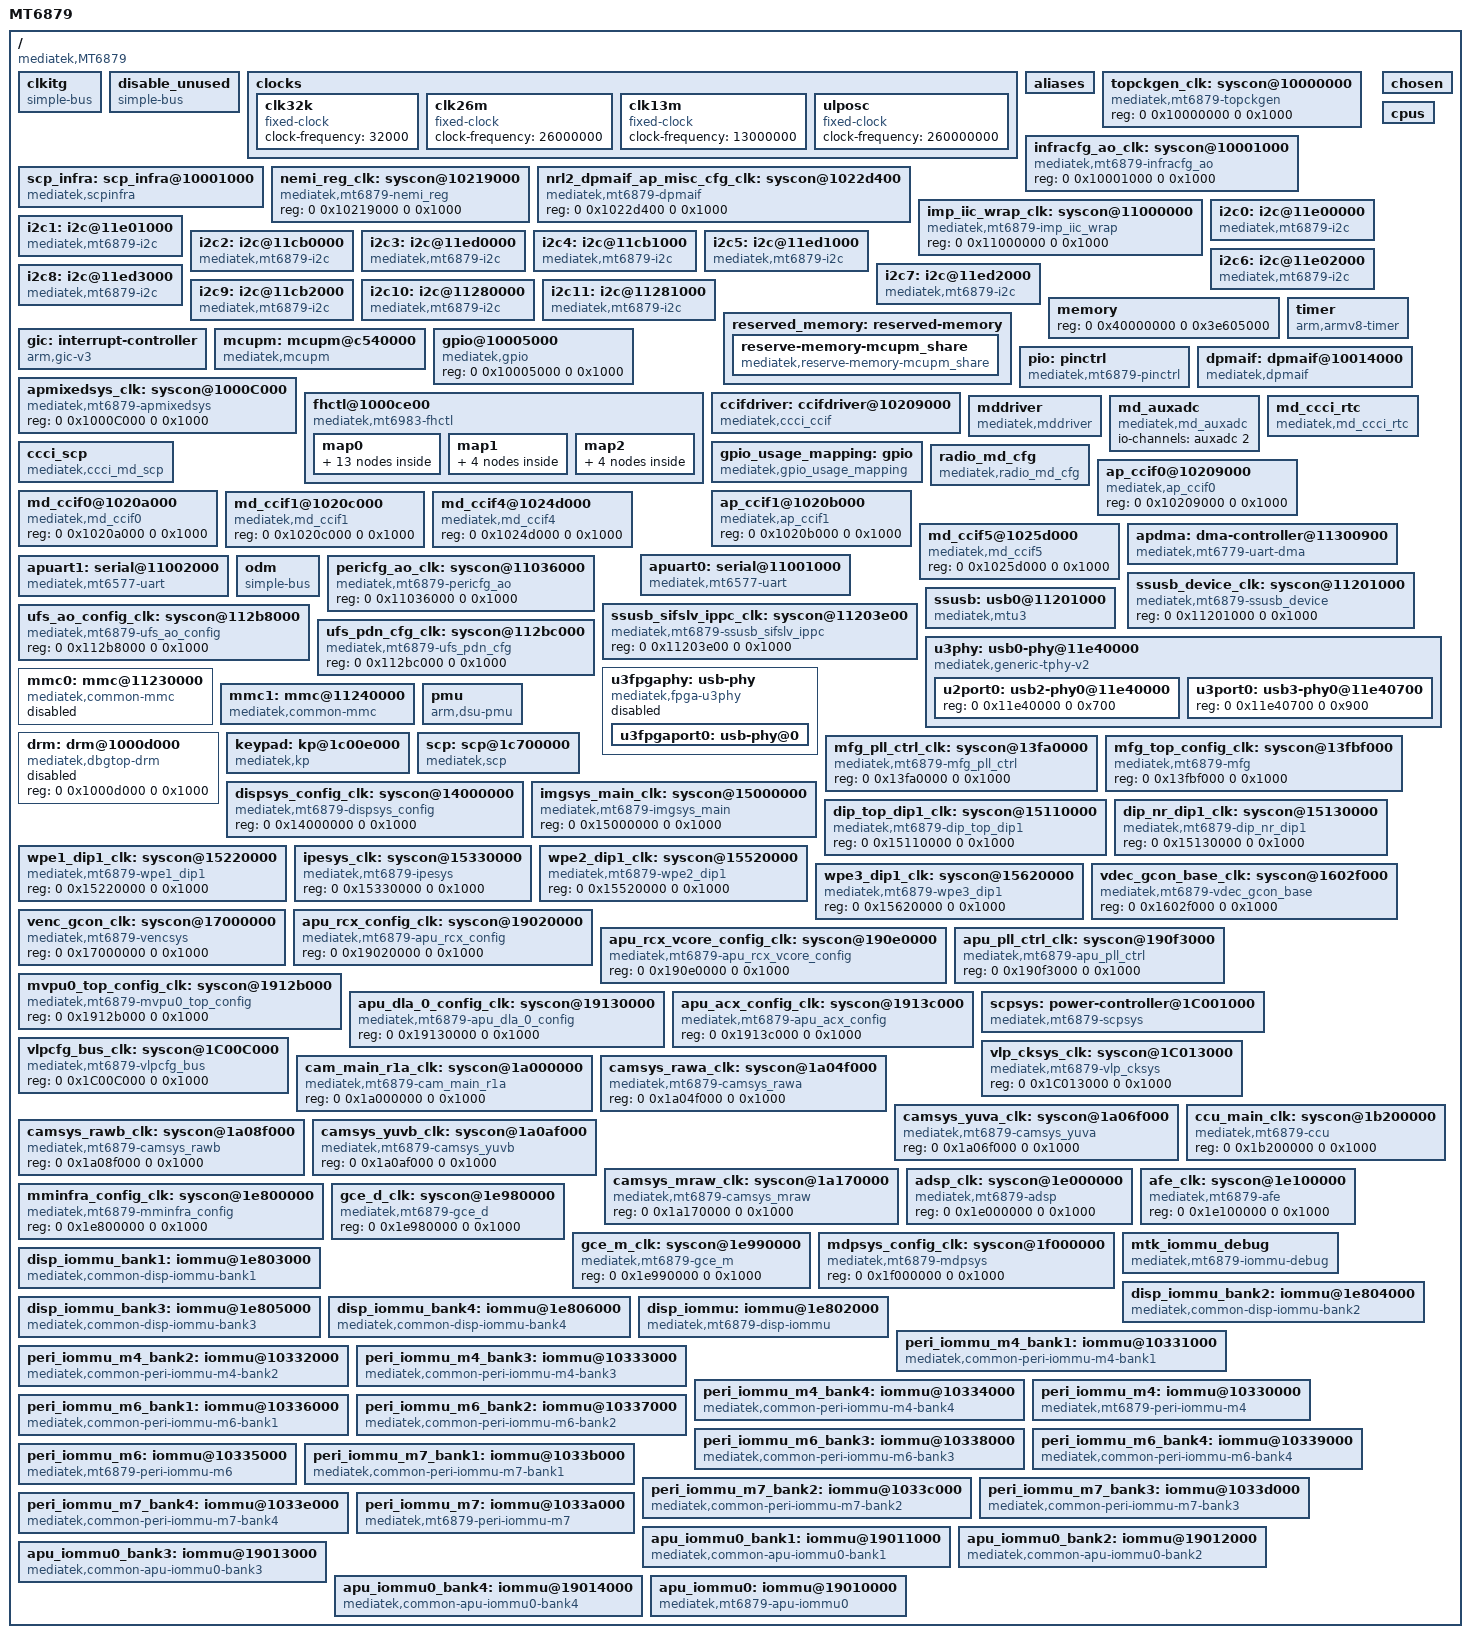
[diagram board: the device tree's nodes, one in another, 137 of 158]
// SPDX-License-Identifier: (GPL-2.0 OR MIT)
/*
 * Copyright (C) 2021 MediaTek Inc.
 */

/dts-v1/;
#include <dt-bindings/clock/mt6879-clk.h>
#include <dt-bindings/interrupt-controller/arm-gic.h>
#include <dt-bindings/interrupt-controller/irq.h>
#include <dt-bindings/phy/phy.h>
#include <dt-bindings/power/mt6879-power.h>
#include <dt-bindings/memory/mt6879-larb-port.h>

/ {
	model = "MT6879";
	compatible = "mediatek,MT6879";
	interrupt-parent = <&gic>;
	#address-cells = <2>;
	#size-cells = <2>;

	clkitg: clkitg {
		compatible = "simple-bus";
	};

	disable_unused: disable_unused {
		compatible = "simple-bus";
	};

	clocks {
		clk32k: clk32k {
			compatible = "fixed-clock";
			#clock-cells = <0>;
			clock-frequency = <32000>;
		};

		clk26m: clk26m {
			compatible = "fixed-clock";
			#clock-cells = <0>;
			clock-frequency = <26000000>;
		};

		clk13m: clk13m {
			compatible = "fixed-clock";
			#clock-cells = <0>;
			clock-frequency = <13000000>;
		};

		ulposc: ulposc {
			compatible = "fixed-clock";
			#clock-cells = <0>;
			clock-frequency = <260000000>;
		};
	};

	aliases {
		i2c0 = &i2c0;
		i2c1 = &i2c1;
		i2c2 = &i2c2;
		i2c3 = &i2c3;
		i2c4 = &i2c4;
		i2c5 = &i2c5;
		i2c6 = &i2c6;
		i2c7 = &i2c7;
		i2c8 = &i2c8;
		i2c9 = &i2c9;
		i2c10 = &i2c10;
		i2c11 = &i2c11;
	};

	topckgen_clk: syscon@10000000 {
		compatible = "mediatek,mt6879-topckgen", "syscon";
		reg = <0 0x10000000 0 0x1000>;
		#clock-cells = <1>;
	};

	infracfg_ao_clk: syscon@10001000 {
		compatible = "mediatek,mt6879-infracfg_ao", "syscon";
		reg = <0 0x10001000 0 0x1000>;
		#clock-cells = <1>;
	};

	scp_infra: scp_infra@10001000 {
	    compatible = "mediatek,scpinfra";
	    reg = <0 0x10001000 0 0x1000>,	/* infracfg_ao */
		  <0 0x10006000 0 0x1000>,	/* spm */
		  <0 0x10000000 0 0x1000>;	/* topckgen */
	    #clock-cells = <1>;
	};

	nemi_reg_clk: syscon@10219000 {
		compatible = "mediatek,mt6879-nemi_reg", "syscon";
		reg = <0 0x10219000 0 0x1000>;
		#clock-cells = <1>;
	};

	nrl2_dpmaif_ap_misc_cfg_clk: syscon@1022d400 {
		compatible = "mediatek,mt6879-dpmaif", "syscon";
		reg = <0 0x1022d400 0 0x1000>;
		#clock-cells = <1>;
	};

	imp_iic_wrap_clk: syscon@11000000 {
		compatible = "mediatek,mt6879-imp_iic_wrap", "syscon";
		reg = <0 0x11000000 0 0x1000>;
		#clock-cells = <1>;
	};

	i2c0: i2c@11e00000 {
		compatible = "mediatek,mt6879-i2c";
		reg = <0 0x11e00000 0 0x1000>,
			<0 0x11300080 0 0x80>;
		/* interrupts = <GIC_SPI 100 IRQ_TYPE_LEVEL_HIGH 0>; */
		/* clocks = <&imp_iic_wrap_e_clk CLK_IMPE_AP_I2C0_RO>, */
			/* <&infracfg_ao_clk CLK_IFRAO_APDMA>; */
		clock-names = "main", "dma";
		clock-div = <1>;
	};

	i2c1: i2c@11e01000 {
		compatible = "mediatek,mt6879-i2c";
		reg = <0 0x11e01000 0 0x1000>,
			<0 0x11300100 0 0x80>;
		/* interrupts = <GIC_SPI 100 IRQ_TYPE_LEVEL_HIGH 0>; */
		/* clocks = <&imp_iic_wrap_e_clk CLK_IMPE_AP_I2C1_RO>, */
			/* <&infracfg_ao_clk CLK_IFRAO_APDMA>; */
		clock-names = "main", "dma";
		clock-div = <1>;
	};

	i2c2: i2c@11cb0000 {
		compatible = "mediatek,mt6879-i2c";
		reg = <0 0x11cb0000 0 0x1000>,
			<0 0x11300180 0 0x100>;
		/* interrupts = <GIC_SPI 100 IRQ_TYPE_LEVEL_HIGH 0>; */
		/* clocks = <&imp_iic_wrap_e_clk CLK_IMPE_AP_I2C2_RO>, */
			/* <&infracfg_ao_clk CLK_IFRAO_APDMA>; */
		clock-names = "main", "dma";
		clock-div = <1>;
	};

	i2c3: i2c@11ed0000 {
		compatible = "mediatek,mt6879-i2c";
		reg = <0 0x11ed0000 0 0x1000>,
			<0 0x11300280 0 0x80>;
		/* interrupts = <GIC_SPI 100 IRQ_TYPE_LEVEL_HIGH 0>; */
		/* clocks = <&imp_iic_wrap_e_clk CLK_IMPE_AP_I2C3_RO>, */
			/* <&infracfg_ao_clk CLK_IFRAO_APDMA>; */
		clock-names = "main", "dma";
		clock-div = <1>;
	};

	i2c4: i2c@11cb1000 {
		compatible = "mediatek,mt6879-i2c";
		reg = <0 0x11cb1000 0 0x1000>,
			<0 0x11300300 0 0x100>;
		/* interrupts = <GIC_SPI 100 IRQ_TYPE_LEVEL_HIGH 0>; */
		/* clocks = <&imp_iic_wrap_e_clk CLK_IMPE_AP_I2C4_RO>, */
			/* <&infracfg_ao_clk CLK_IFRAO_APDMA>; */
		clock-names = "main", "dma";
		clock-div = <1>;
	};

	i2c5: i2c@11ed1000 {
		compatible = "mediatek,mt6879-i2c";
		reg = <0 0x11ed1000 0 0x1000>,
			<0 0x11300400 0 0x80>;
		/* interrupts = <GIC_SPI 100 IRQ_TYPE_LEVEL_HIGH 0>; */
		/* clocks = <&imp_iic_wrap_e_clk CLK_IMPE_AP_I2C5_RO>, */
			/* <&infracfg_ao_clk CLK_IFRAO_APDMA>; */
		clock-names = "main", "dma";
		clock-div = <1>;
	};

	i2c6: i2c@11e02000 {
		compatible = "mediatek,mt6879-i2c";
		reg = <0 0x11e02000 0 0x1000>,
			<0 0x11300480 0 0x80>;
		/* interrupts = <GIC_SPI 100 IRQ_TYPE_LEVEL_HIGH 0>; */
		/* clocks = <&imp_iic_wrap_e_clk CLK_IMPE_AP_I2C6_RO>, */
			/* <&infracfg_ao_clk CLK_IFRAO_APDMA>; */
		clock-names = "main", "dma";
		clock-div = <1>;
	};

	i2c7: i2c@11ed2000 {
		compatible = "mediatek,mt6879-i2c";
		reg = <0 0x11ed2000 0 0x1000>,
			<0 0x11300500 0 0x100>;
		/* interrupts = <GIC_SPI 100 IRQ_TYPE_LEVEL_HIGH 0>; */
		/* clocks = <&imp_iic_wrap_e_clk CLK_IMPE_AP_I2C7_RO>, */
			/* <&infracfg_ao_clk CLK_IFRAO_APDMA>; */
		clock-names = "main", "dma";
		clock-div = <1>;
	};

	i2c8: i2c@11ed3000 {
		compatible = "mediatek,mt6879-i2c";
		reg = <0 0x11ed3000 0 0x1000>,
			<0 0x11300600 0 0x100>;
		/* interrupts = <GIC_SPI 100 IRQ_TYPE_LEVEL_HIGH 0>; */
		/* clocks = <&imp_iic_wrap_e_clk CLK_IMPE_AP_I2C8_RO>, */
			/* <&infracfg_ao_clk CLK_IFRAO_APDMA>; */
		clock-names = "main", "dma";
		clock-div = <1>;
	};

	i2c9: i2c@11cb2000 {
		compatible = "mediatek,mt6879-i2c";
		reg = <0 0x11cb2000 0 0x1000>,
			<0 0x11300700 0 0x100>;
		/* interrupts = <GIC_SPI 100 IRQ_TYPE_LEVEL_HIGH 0>; */
		/* clocks = <&imp_iic_wrap_e_clk CLK_IMPE_AP_I2C9_RO>, */
			/* <&infracfg_ao_clk CLK_IFRAO_APDMA>; */
		clock-names = "main", "dma";
		clock-div = <1>;
	};

	i2c10: i2c@11280000 {
		compatible = "mediatek,mt6879-i2c";
		reg = <0 0x11280000 0 0x1000>,
			<0 0x11300800 0 0x80>;
		/* interrupts = <GIC_SPI 100 IRQ_TYPE_LEVEL_HIGH 0>; */
		/* clocks = <&imp_iic_wrap_e_clk CLK_IMPE_AP_I2C10_RO>, */
			/* <&infracfg_ao_clk CLK_IFRAO_APDMA>; */
		clock-names = "main", "dma";
		clock-div = <1>;
	};

	i2c11: i2c@11281000 {
		compatible = "mediatek,mt6879-i2c";
		reg = <0 0x11281000 0 0x1000>,
			<0 0x11300880 0 0x80>;
		/* interrupts = <GIC_SPI 100 IRQ_TYPE_LEVEL_HIGH 0>; */
		/* clocks = <&imp_iic_wrap_e_clk CLK_IMPE_AP_I2C11_RO>, */
			/* <&infracfg_ao_clk CLK_IFRAO_APDMA>; */
		clock-names = "main", "dma";
		clock-div = <1>;
	};

	/* chosen */
	chosen: chosen {
		bootargs = "console=tty0 console=ttyS0,921600n1 root=/dev/ram \
			vmalloc=400M slub_debug=OFZPU swiotlb=noforce \
			firmware_class.path=/vendor/firmware \
			page_owner=on";
	};

	cpus {
	};

	memory {
		device_type = "memory";
		reg = <0 0x40000000 0 0x3e605000>;
	};

	reserved_memory: reserved-memory {
		#address-cells = <2>;
		#size-cells = <2>;
		ranges;

		reserve-memory-mcupm_share {
			compatible = "mediatek,reserve-memory-mcupm_share";
			no-map;
			status = "okay";
			size = <0 0x610000>; /* 6M + 64K */
			alignment = <0 0x10000>;
			alloc-ranges = <0 0x40000000 0 0x60000000>;
		};
	};

	gic: interrupt-controller {
		compatible = "arm,gic-v3";
		#interrupt-cells = <3>;
		#address-cells = <2>;
		#size-cells = <2>;
		#redistributor-regions = <1>;
		interrupt-parent = <&gic>;
		interrupt-controller;
		reg = <0 0x0c000000 0 0x40000>, // distributor
		      <0 0x0c040000 0 0x200000>; // redistributor
		interrupts = <GIC_PPI 9 IRQ_TYPE_LEVEL_HIGH>;
	};

	timer: timer {
		compatible = "arm,armv8-timer";
		interrupt-parent = <&gic>;
		interrupts = <GIC_PPI 13 IRQ_TYPE_LEVEL_HIGH>,
			<GIC_PPI 14 IRQ_TYPE_LEVEL_HIGH>,
			<GIC_PPI 11 IRQ_TYPE_LEVEL_HIGH>,
			<GIC_PPI 10 IRQ_TYPE_LEVEL_HIGH>;
		clock-frequency = <13000000>;
	};

	mcupm: mcupm@c540000 {
		compatible = "mediatek,mcupm";
		reg = <0 0x0c540000 0 0x22000>,
		      <0 0x0c55fb00 0 0xa0>,
		      <0 0x0c562004 0 0x4>,
		      <0 0x0c562018 0 0x4>,
		      <0 0x0c562000 0 0x4>,
		      <0 0x0c562010 0 0x4>,
		      <0 0x0c55fba0 0 0xa0>,
		      <0 0x0c562004 0 0x4>,
		      <0 0x0c562018 0 0x4>,
		      <0 0x0c562000 0 0x4>,
		      <0 0x0c562010 0 0x4>,
		      <0 0x0c55fc40 0 0xa0>,
		      <0 0x0c562004 0 0x4>,
		      <0 0x0c562018 0 0x4>,
		      <0 0x0c562000 0 0x4>,
		      <0 0x0c562010 0 0x4>,
		      <0 0x0c55fce0 0 0xa0>,
		      <0 0x0c562004 0 0x4>,
		      <0 0x0c562018 0 0x4>,
		      <0 0x0c562000 0 0x4>,
		      <0 0x0c562010 0 0x4>,
		      <0 0x0c55fd80 0 0xa0>,
		      <0 0x0c562004 0 0x4>,
		      <0 0x0c562018 0 0x4>,
		      <0 0x0c562000 0 0x4>,
		      <0 0x0c562010 0 0x4>,
		      <0 0x0c55fe20 0 0xa0>,
		      <0 0x0c562004 0 0x4>,
		      <0 0x0c562018 0 0x4>,
		      <0 0x0c562000 0 0x4>,
		      <0 0x0c562010 0 0x4>,
		      <0 0x0c55fec0 0 0xa0>,
		      <0 0x0c562004 0 0x4>,
		      <0 0x0c562018 0 0x4>,
		      <0 0x0c562000 0 0x4>,
		      <0 0x0c562010 0 0x4>,
		      <0 0x0c55ff60 0 0xa0>,
		      <0 0x0c562004 0 0x4>,
		      <0 0x0c562018 0 0x4>,
		      <0 0x0c562000 0 0x4>,
		      <0 0x0c562010 0 0x4>;
		reg-names = "mcupm_base",
			    "mbox0_base",
			    "mbox0_set",
			    "mbox0_clr",
			    "mbox0_send",
			    "mbox0_recv",
			    "mbox1_base",
			    "mbox1_set",
			    "mbox1_clr",
			    "mbox1_send",
			    "mbox1_recv",
			    "mbox2_base",
			    "mbox2_set",
			    "mbox2_clr",
			    "mbox2_send",
			    "mbox2_recv",
			    "mbox3_base",
			    "mbox3_set",
			    "mbox3_clr",
			    "mbox3_send",
			    "mbox3_recv",
			    "mbox4_base",
			    "mbox4_set",
			    "mbox4_clr",
			    "mbox4_send",
			    "mbox4_recv",
			    "mbox5_base",
			    "mbox5_set",
			    "mbox5_clr",
			    "mbox5_send",
			    "mbox5_recv",
			    "mbox6_base",
			    "mbox6_set",
			    "mbox6_clr",
			    "mbox6_send",
			    "mbox6_recv",
			    "mbox7_base",
			    "mbox7_set",
			    "mbox7_clr",
			    "mbox7_send",
			    "mbox7_recv";
		interrupts = <GIC_SPI 24 IRQ_TYPE_LEVEL_HIGH>,
			     <GIC_SPI 25 IRQ_TYPE_LEVEL_HIGH>,
			     <GIC_SPI 26 IRQ_TYPE_LEVEL_HIGH>,
			     <GIC_SPI 27 IRQ_TYPE_LEVEL_HIGH>,
			     <GIC_SPI 28 IRQ_TYPE_LEVEL_HIGH>,
			     <GIC_SPI 29 IRQ_TYPE_LEVEL_HIGH>,
			     <GIC_SPI 30 IRQ_TYPE_LEVEL_HIGH>,
			     <GIC_SPI 31 IRQ_TYPE_LEVEL_HIGH>;
		interrupt-names = "mbox0",
				  "mbox1",
				  "mbox2",
				  "mbox3",
				  "mbox4",
				  "mbox5",
				  "mbox6",
				  "mbox7";
	};

	gpio@10005000 {
		compatible = "mediatek,gpio";
		reg = <0 0x10005000 0 0x1000>;
	};

	pio: pinctrl {
		compatible = "mediatek,mt6879-pinctrl";
		reg = <0 0x10005000 0 0x1000>,
		      <0 0x11b00000 0 0x1000>,
		      <0 0x11c20000 0 0x1000>,
		      <0 0x11c40000 0 0x1000>,
		      <0 0x11d30000 0 0x1000>,
		      <0 0x11d40000 0 0x1000>,
		      <0 0x11e10000 0 0x1000>,
		      <0 0x11e30000 0 0x1000>,
		      <0 0x11ec0000 0 0x1000>;
 		reg-names = "gpio",
 			    "iocfg_lb",
			    "iocfg_rm",
			    "iocfg_rb",
			    "iocfg_bm",
			    "iocfg_br",
			    "iocfg_lm",
			    "iocfg_lt",
			    "iocfg_rt";
		gpio-controller;
		#gpio-cells = <2>;
		gpio-ranges = <&pio 0 0 217>;
	};

	apmixedsys_clk: syscon@1000C000 {
		compatible = "mediatek,mt6879-apmixedsys", "syscon";
		reg = <0 0x1000C000 0 0x1000>;
		#clock-cells = <1>;
	};

	fhctl@1000ce00 {
		compatible = "mediatek,mt6983-fhctl";
		reg = <0 0x1000ce00 0 0x200>, //AP FHCTL base
			  <0 0x1000c000 0 0xe00>, //APMIX base

			  <0 0x190f3e00 0 0x200>, //APU EN
			  <0 0x190f3000 0 0x100>, //APU APMIX

			  <0 0x13fa0e00 0 0x200>, //GPU EN
			  <0 0x13fa0000 0 0x100>; //GPU APMIX

		map0 {
			domain = "top";
			method = "fhctl-mcupm";
			armpll_ll {
				fh-id = <0>;
				pll-id = <999>;
			};
			armpll_bl {
				fh-id = <1>;
				pll-id = <999>;
			};
			armpll_b {
				fh-id = <2>;
				pll-id = <999>;
			};
			ccipll {
				fh-id = <3>;
				pll-id = <999>;
			};
			mempll {
				fh-id = <4>;
				pll-id = <999>;
			};
			emipll {
				fh-id = <5>;
				pll-id = <999>;
			};
			mpll {
				fh-id = <6>;
				pll-id = <999>;
			};
			mmpll {
				fh-id = <7>;
				pll-id = <999>;
			};
			mainpll {
				fh-id = <8>;
				pll-id = <999>;
			};
			msdcpll {
				fh-id = <9>;
				pll-id = <999>;
			};
			adsppll {
				fh-id = <10>;
				pll-id = <999>;
			};
			imgpll {
				fh-id = <11>;
				pll-id = <999>;
			};
			tvdpll {
				fh-id = <12>;
				pll-id = <999>;
			};
		};

		map1 {
			domain = "apu";
			method = "fhctl-ap";
			apupll0 {
				fh-id = <0>;
				pll-id = <999>;
			};
			apupll1 {
				fh-id = <1>;
				pll-id = <999>;
			};
			apupll2 {
				fh-id = <2>;
				pll-id = <999>;
			};
			apupll3 {
				fh-id = <3>;
				pll-id = <999>;
			};
		};

		map2 {
			domain = "gpu";
			method = "fhctl-ap";
			mfgpll0 {
				fh-id = <0>;
				pll-id = <999>;
			};
			mfgpll1 {
				fh-id = <1>;
				pll-id = <999>;
			};
			mfgpll2 {
				fh-id = <2>;
				pll-id = <999>;
			};
			mfgpll3 {
				fh-id = <3>;
				pll-id = <999>;
			};
		};
	};

	dpmaif:dpmaif@10014000 {
		compatible = "mediatek,dpmaif";
		reg = <0 0x10014000 0 0x1000>, /*AO_UL*/
			<0 0x1022d000 0 0x1000>, /*PD_UL*/
			<0 0x1022c000 0 0x1000>, /*PD_MD_MISC*/
			<0 0x1022e000 0 0x1000>; /*SRAM*/
		interrupts = <GIC_SPI 262 IRQ_TYPE_LEVEL_HIGH 0>, /* rxq0 irq: 166 262 294 */
			<GIC_SPI 667 IRQ_TYPE_LEVEL_HIGH 0>; /* new rxq1 irq: 571 667 699 */
		mediatek,dpmaif_ver = <3>;
		mediatek,dpmaif_cap = <0x00000000>;
		clocks = <&infracfg_ao_clk CLK_IFRAO_DPMAIF_MAIN>,
				<&infracfg_ao_clk CLK_IFRAO_CLDMA_BCLK>,
			    <&infracfg_ao_clk CLK_IFRAO_RG_MMW_DPMAIF26M_CK>;
		clock-names = "infra-dpmaif-clk",
			    "infra-dpmaif-blk-clk",
			    "infra-dpmaif-rg-mmw-clk";
	};

	ccifdriver:ccifdriver@10209000 {
		compatible = "mediatek,ccci_ccif";
		reg = <0 0x10209000 0 0x1000>, /*AP_CCIF_BASE*/
			<0 0x1020a000 0 0x1000>; /*MD_CCIF_BASE*/
		mediatek,sram_size = <512>;
		/* CCIF0 282; CCIF0 283 */
		interrupts = <GIC_SPI 250 IRQ_TYPE_LEVEL_HIGH 0>,
			     <GIC_SPI 251 IRQ_TYPE_LEVEL_HIGH 0>;
		clocks = <&infracfg_ao_clk CLK_IFRAO_CCIF_AP>,
			<&infracfg_ao_clk CLK_IFRAO_CCIF_MD>,
			<&infracfg_ao_clk CLK_IFRAO_CCIF1_AP>,
			<&infracfg_ao_clk CLK_IFRAO_CCIF1_MD>,
			<&infracfg_ao_clk CLK_IFRAO_CCIF4_MD>,
			<&infracfg_ao_clk CLK_IFRAO_CCIF5_MD>;
		clock-names = "infra-ccif-ap",
			"infra-ccif-md",
			"infra-ccif1-ap",
			"infra-ccif1-md",
			"infra-ccif4-md",
			"infra-ccif5-md";
	};

	mddriver:mddriver {
		compatible = "mediatek,mddriver";
		/* bit0~3: CLDMA|CCIF|DPMAIF */
		mediatek,mdhif_type = <6>;
		mediatek,md_id = <0>;
		mediatek,ap_plat_info = <6893>;
		mediatek,md_generation = <6297>;
		mediatek,offset_apon_md1 = <0x2844>;
		mediatek,cldma_capability = <6>;
		/* bit0~1: srcclkena|srclken_o1_on */
		mediatek,srclkena_setting = <0>;
		/* srclken_o1 set value |= 1<<21 */
		mediatek,srclken_o1 = <0>;
		reg = <0 0x10209000 0 0x1000>, /*AP_CCIF_BASE*/
			<0 0x1020a000 0 0x1000>; /*MD_CCIF_BASE*/
		/* GIC ID:MDWDT 291; CCIF0 282; CCIF0 283 */
		interrupts = <GIC_SPI 259 IRQ_TYPE_EDGE_RISING 0>,
			     <GIC_SPI 250 IRQ_TYPE_LEVEL_HIGH 0>,
			     <GIC_SPI 251 IRQ_TYPE_LEVEL_HIGH 0>;
		power-domains = <&scpsys MT6879_POWER_DOMAIN_MD>;
		ccci-infracfg = <&infracfg_ao_clk>;
		ccci-topckgen = <&topckgen_clk>;
		ccci_spmsleep = <&sleep>;
	};

	md_auxadc:md_auxadc {
		compatible = "mediatek,md_auxadc";
		io-channels = <&auxadc 2>;
		io-channel-names = "md-channel",
			"md-battery";
	};

	md_ccci_rtc:md_ccci_rtc {
		compatible = "mediatek,md_ccci_rtc";
		nvmem-cells = <&ext_32k>;
		nvmem-cell-names = "external-32k";
	};

	ccci_scp:ccci_scp {
		compatible = "mediatek,ccci_md_scp";
		clocks = <&infracfg_ao_clk CLK_IFRAO_CCIF2_AP>,
			<&infracfg_ao_clk CLK_IFRAO_CCIF2_MD>;
		clock-names = "infra-ccif2-ap",
			"infra-ccif2-md";
	};

	gpio_usage_mapping:gpio {
		compatible = "mediatek,gpio_usage_mapping";
	};

	radio_md_cfg:radio_md_cfg {
		compatible = "mediatek,radio_md_cfg";
	};

	ap_ccif0@10209000 {
		compatible = "mediatek,ap_ccif0";
		reg = <0 0x10209000 0 0x1000>;
	};

	md_ccif0@1020a000 {
		compatible = "mediatek,md_ccif0";
		reg = <0 0x1020a000 0 0x1000>;
	};

	ap_ccif1@1020b000 {
		compatible = "mediatek,ap_ccif1";
		reg = <0 0x1020b000 0 0x1000>;
	};

	md_ccif1@1020c000 {
		compatible = "mediatek,md_ccif1";
		reg = <0 0x1020c000 0 0x1000>;
	};

	md_ccif4@1024d000 {
		compatible = "mediatek,md_ccif4";
		reg = <0 0x1024d000 0 0x1000>;
	};

	md_ccif5@1025d000 {
		compatible = "mediatek,md_ccif5";
		reg = <0 0x1025d000 0 0x1000>;
	};

	apdma: dma-controller@11300900 {
		compatible = "mediatek,mt6779-uart-dma";
		reg = <0 0x11300900 0 0x80>,
		      <0 0x11300980 0 0x80>,
		      <0 0x11300a00 0 0x80>,
		      <0 0x11300a80 0 0x80>;
		interrupts = <GIC_SPI 175 IRQ_TYPE_LEVEL_HIGH>,
			     <GIC_SPI 176 IRQ_TYPE_LEVEL_HIGH>,
			     <GIC_SPI 177 IRQ_TYPE_LEVEL_HIGH>,
			     <GIC_SPI 178 IRQ_TYPE_LEVEL_HIGH>;
	};

	apuart0: serial@11001000 {
		compatible = "mediatek,mt6577-uart";
		reg = <0 0x11001000 0 0x1000>;
		interrupts = <GIC_SPI 141 IRQ_TYPE_LEVEL_HIGH>;
		dmas = <&apdma 0
				&apdma 1>;
		dma-names = "tx", "rx";
	};

	apuart1: serial@11002000 {
		compatible = "mediatek,mt6577-uart";
		reg = <0 0x11002000 0 0x1000>;
		interrupts = <GIC_SPI 142 IRQ_TYPE_LEVEL_HIGH>;
		dmas = <&apdma 2
				&apdma 3>;
		dma-names = "tx", "rx";
	};

	odm: odm {
		compatible = "simple-bus";
		/* reserved for overlay by odm */
	};

	pericfg_ao_clk: syscon@11036000 {
		compatible = "mediatek,mt6879-pericfg_ao", "syscon";
		reg = <0 0x11036000 0 0x1000>;
		#clock-cells = <1>;
	};

	ssusb_device_clk: syscon@11201000 {
		compatible = "mediatek,mt6879-ssusb_device", "syscon";
		reg = <0 0x11201000 0 0x1000>;
		#clock-cells = <1>;
	};

	ssusb_sifslv_ippc_clk: syscon@11203e00 {
		compatible = "mediatek,mt6879-ssusb_sifslv_ippc", "syscon";
		reg = <0 0x11203e00 0 0x1000>;
		#clock-cells = <1>;
	};

	ufs_ao_config_clk: syscon@112b8000 {
		compatible = "mediatek,mt6879-ufs_ao_config", "syscon";
		reg = <0 0x112b8000 0 0x1000>;
		#clock-cells = <1>;
	};

	ufs_pdn_cfg_clk: syscon@112bc000 {
		compatible = "mediatek,mt6879-ufs_pdn_cfg", "syscon";
		reg = <0 0x112bc000 0 0x1000>;
		#clock-cells = <1>;
	};

	ssusb: usb0@11201000 {
		compatible = "mediatek,mtu3";
		reg = <0 0x11201000 0 0x2e00>,
			<0 0x11203e00 0 0x0100>;
		reg-names = "mac", "ippc";
		interrupts = <GIC_SPI 128 IRQ_TYPE_LEVEL_HIGH 0>;
		phy-cells = <1>;
		phys = <&u2port0 PHY_TYPE_USB2>,
			 <&u3port0 PHY_TYPE_USB3>;
		#address-cells = <2>;
		#size-cells = <2>;
		ranges;
		dr_mode = "otg";
		maximum-speed = "high-speed";
		mediatek,force-vbus;
		mediatek,clk-mgr;
		mediatek,usb3-drd;
		usb-role-switch;
	};

	u3phy: usb0-phy@11e40000 {
		compatible = "mediatek,generic-tphy-v2";
		#address-cells = <2>;
		#size-cells = <2>;
		ranges;

		u2port0: usb2-phy0@11e40000 {
			reg = <0 0x11e40000 0 0x700>;
			#phy-cells = <1>;
		};

		u3port0: usb3-phy0@11e40700 {
			reg = <0 0x11e40700 0 0x900>;
			#phy-cells = <1>;
		};
	};

	u3fpgaphy: usb-phy {
		compatible = "mediatek,fpga-u3phy";
		mediatek,ippc = <0x11203e00>;
		#address-cells = <2>;
		#size-cells = <2>;
		fpga_i2c_physical_base = <0x11cb0000>;
		status = "disabled";

		u3fpgaport0: usb-phy@0 {
			chip-id= <0xa60931a>;
			port = <0>;
			pclk_phase = <23>;
			#phy-cells = <1>;
		};
	};

	mmc0: mmc@11230000 {
		compatible = "mediatek,common-mmc";
		reg = <0 0x11230000 0 0x10000>,
		      <0 0x11f50000 0 0x1000>;
		interrupts = <GIC_SPI 99 IRQ_TYPE_LEVEL_HIGH 0>;
		status = "disabled";
	};

	mmc1: mmc@11240000 {
		compatible = "mediatek,common-mmc";
		reg = <0 0x11240000 0 0x1000>,
		      <0 0x11c00000 0 0x1000>;
		interrupts = <GIC_SPI 135 IRQ_TYPE_LEVEL_HIGH 0>;
#if 0
		clocks = <&topckgen_clk CLK_TOP_MSDC30_1_SEL>,
			 <&infracfg_ao_clk CLK_IFRAO_MSDC1>,
			 <&infracfg_ao_clk CLK_IFRAO_MSDC1_SRC>;
		clock-names = "source", "hclk", "source_cg";
#endif
	};

	pmu {
		compatible = "arm,dsu-pmu";
		interrupt-parent = <&gic>;
		interrupts = <GIC_PPI 7 IRQ_TYPE_LEVEL_HIGH>;
	};

	drm: drm@1000d000 {
		compatible = "mediatek,dbgtop-drm";
		reg = <0 0x1000d000 0 0x1000>;
		status = "disabled";
	};

	keypad: kp@1c00e000 {
		compatible = "mediatek,kp";
		reg = <0 0x1c00e000 0 0x1000>;
		interrupts = <GIC_SPI 106 IRQ_TYPE_EDGE_RISING 0>;
		mediatek,key-debounce-ms = <1024>;
		mediatek,hw-map-num = <72>;
		mediatek,hw-init-map = <114 0 0 0 0 0 0 0 0 0 0 0 0
					0 0 0 0 0 0 0 0 0 0 0 0 0 0
					0 0 0 0 0 0 0 0 0 0 0 0 0 0
					0 0 0 0 0 0 0 0 0 0 0 0 0 0
					0 0 0 0 0 0 0 0 0 0 0 0 0 0
					0 0 0>;
		clocks = <&clk26m>;
		clock-names = "kpd";
	};

	scp: scp@1c700000 {
		compatible = "mediatek,scp";
		status = "okay";
		reg = <0 0x1c400000 0 0x100000>, /* tcm */
		      <0 0x1c724000 0 0x1000>, /* cfg */
		      <0 0x1c721000 0 0x1000>, /* clk*/
		      <0 0x1c730000 0 0x1000>, /* cfg core0 */
		      <0 0x1c740000 0 0x1000>, /* cfg core1 */
		      <0 0x1c752000 0 0x1000>, /* bus tracker */
		      <0 0x1c760000 0 0x40000>, /* llc */
		      <0 0x1c7a5000 0 0x4>, /* cfg_sec */
		      <0 0x1c7fb000 0 0x100>, /* mbox0 base */
		      <0 0x1c7fb100 0 0x4>, /* mbox0 set */
		      <0 0x1c7fb10c 0 0x4>, /* mbox0 clr */
		      <0 0x1c7a5020 0 0x4>, /* mbox0 init */
		      <0 0x1c7fc000 0 0x100>, /* mbox1 base */
		      <0 0x1c7fc100 0 0x4>, /* mbox1 set */
		      <0 0x1c7fc10c 0 0x4>, /* mbox1 clr */
		      <0 0x1c7a5024 0 0x4>, /* mbox1 init */
		      <0 0x1c7fd000 0 0x100>, /* mbox2 base */
		      <0 0x1c7fd100 0 0x4>, /* mbox2 set */
		      <0 0x1c7fd10c 0 0x4>, /* mbox2 clr */
		      <0 0x1c7a5028 0 0x4>, /* mbox2 init */
		      <0 0x1c7fe000 0 0x100>, /* mbox3 base */
		      <0 0x1c7fe100 0 0x4>, /* mbox3 set */
		      <0 0x1c7fe10c 0 0x4>, /* mbox3 clr */
		      <0 0x1c7a502c 0 0x4>, /* mbox3 init */
		      <0 0x1c7ff000 0 0x100>, /* mbox4 base */
		      <0 0x1c7ff100 0 0x4>, /* mbox4 set */
		      <0 0x1c7ff10c 0 0x4>, /* mbox4 clr */
		      <0 0x1c7a5030 0 0x4>; /* mbox4 init */

		reg-names = "scp_sram_base",
			    "scp_cfgreg",
			    "scp_clkreg",
			    "scp_cfgreg_core0",
			    "scp_cfgreg_core1",
			    "scp_bus_tracker",
			    "scp_l1creg",
			    "scp_cfgreg_sec",
			    "mbox0_base",
			    "mbox0_set",
			    "mbox0_clr",
			    "mbox0_init",
			    "mbox1_base",
			    "mbox1_set",
			    "mbox1_clr",
			    "mbox1_init",
			    "mbox2_base",
			    "mbox2_set",
			    "mbox2_clr",
			    "mbox2_init",
			    "mbox3_base",
			    "mbox3_set",
			    "mbox3_clr",
			    "mbox3_init",
			    "mbox4_base",
			    "mbox4_set",
			    "mbox4_clr",
			    "mbox4_init";

		interrupts = <GIC_SPI 569 IRQ_TYPE_LEVEL_HIGH 0>,
			     <GIC_SPI 570 IRQ_TYPE_LEVEL_HIGH 0>,
			     <GIC_SPI 571 IRQ_TYPE_LEVEL_HIGH 0>,
			     <GIC_SPI 572 IRQ_TYPE_LEVEL_HIGH 0>,
			     <GIC_SPI 573 IRQ_TYPE_LEVEL_HIGH 0>,
			     <GIC_SPI 574 IRQ_TYPE_LEVEL_HIGH 0>,
			     <GIC_SPI 575 IRQ_TYPE_LEVEL_HIGH 0>;

		interrupt-names = "ipc0",
				  "ipc1",
				  "mbox0",
				  "mbox1",
				  "mbox2",
				  "mbox3",
				  "mbox4";

		core_0 = "enable";
		scp_hwccf = "enable";
		scp_sramSize = <0x00100000>;
		core_nums = <1>;	/* core number */
		twohart = <1>;		/* two hart arch */
		mbox_count = <5>;
		/* id, mbox, send_size*/
		send_table =
		< 0 0  9>,/* IPI_OUT_AUDIO_VOW_1 */
		<14 0  1>,/* IPI_OUT_DVFS_SET_FREQ_1 */
		<15 0  2>,/* IPI_OUT_C_SLEEP_1 */
		<16 0  1>,/* IPI_OUT_TEST_1 */
		//<24 0  6>,/* IPI_OUT_SCP_MPOOL_1 */
		<17 1  6>,/* IPI_OUT_LOGGER_CTRL */
		<18 1  2>,/* IPI_OUT_SCPCTL_1 */
		< 4 2  1>,/* IPI_OUT_DVFS_SET_FREQ_0 */
		< 5 2  2>,/* IPI_OUT_C_SLEEP_0 */
		<35 2  2>,/* IPI_OUT_SCP_HWCCF_DEBUG */
		< 6 2  1>,/* IPI_OUT_TEST_0 */
		//<11 2  6>,/* IPI_OUT_SCP_MPOOL_0 */
		<33 2  3>,/* IPI_OUT_SCP_CONNSYS */
		< 3 3  2>,/* IPI_OUT_APCCCI_0 */
		<26 3  9>,/* IPI_OUT_AUDIO_ULTRA_SND_0 */
		<29 4 16>,/* IPI_OUT_SENSOR_CTRL */
		<31 4  7>;/* IPI_OUT_SENSOR_NOTIFY */

		/* id, mbox, recv_size, recv_opt */
		recv_table =
		< 1 0  2 0>,/* IPI_IN_AUDIO_VOW_ACK_1 */
		< 2 0 26 0>,/* IPI_IN_AUDIO_VOW_1 */
		<15 0  1 1>,/* IPI_OUT_C_SLEEP_1 */
		//<25 0  6 0>,/* IPI_IN_SCP_MPOOL_1 */
		<20 1 10 0>,/* IPI_IN_SCP_ERROR_INFO_1 */
		<21 1  6 0>,/* IPI_IN_LOGGER_CTRL */
		<22 1  1 0>,/* IPI_IN_SCP_READY_1 */
		< 5 2  1 1>,/* IPI_OUT_C_SLEEP_0 */
		< 8 2 10 0>,/* IPI_IN_SCP_ERROR_INFO_0 */
		//<12 2  6 0>,/* IPI_IN_SCP_MPOOL_0 */
		<34 2  3 0>,/* IPI_IN_SCP_CONNSYS */
		< 7 3  2 0>,/* IPI_IN_APCCCI_0 */
		<28 3  5 0>,/* IPI_IN_AUDIO_ULTRA_SND_0 */
		<27 3  2 0>,/* IPI_IN_AUDIO_ULTRA_SND_ACK_0 */
		<30 4  2 0>,/* IPI_IN_SENSOR_CTRL */
		<32 4  7 0>;/* IPI_IN_SENSOR_NOTIFY */

		//legacy_table = 	<11>, /* out_id_0 IPI_OUT_SCP_MPOOL_0 */
		//		<24>, /* out_id_1 IPI_OUT_SCP_MPOOL_1 */
		//		<12>, /* in_id_0 IPI_IN_SCP_MPOOL_0 */
		//		<12>, /* in_id_1 IPI_IN_SCP_MPOOL_0 */
		//		<6>, /* out_size */
		//		<6>; /* in_size */

		scp_feature_tbl = <0 5>,   /* vow */
				  <1 29>,  /* sensor */
				  <2 26>,  /* flp */
				  <3 0>,   /* rtos */
				  <4 200>, /* speaker */
				  <5 77>,  /* vcore */
				  <6 200>, /* barge in */
				  <7 10>;  /* vow dump */
		scp_mem_key = "mediatek,reserve-memory-scp_share";
		scp_mem_tbl = <0 0x4A700>, /* vow */
			      <1 0x100000>, /* sensor main*/
			      <2 0x180000>, /* logger */
			      <3 0x19000>, /* audio */
			      <7 0x10000>, /* sensor supper*/
			      <8 0x1000>, /* sensor list */
			      <9 0x2000>; /* sensor debug */

		memorydump = <0x100000>, /* l2tcm */
			     <0x03c000>, /* l1c */
			     <0x003c00>, /* regdump */
			     <0x000400>, /* trace buffer */
			     <0x100000>; /* dram */
	};

	mfg_pll_ctrl_clk: syscon@13fa0000 {
		compatible = "mediatek,mt6879-mfg_pll_ctrl", "syscon";
		reg = <0 0x13fa0000 0 0x1000>;
		#clock-cells = <1>;
	};

	mfg_top_config_clk: syscon@13fbf000 {
		compatible = "mediatek,mt6879-mfg", "syscon";
		reg = <0 0x13fbf000 0 0x1000>;
		#clock-cells = <1>;
	};

	dispsys_config_clk: syscon@14000000 {
		compatible = "mediatek,mt6879-dispsys_config", "syscon";
		reg = <0 0x14000000 0 0x1000>;
		#clock-cells = <1>;
	};

	imgsys_main_clk: syscon@15000000 {
		compatible = "mediatek,mt6879-imgsys_main", "syscon";
		reg = <0 0x15000000 0 0x1000>;
		#clock-cells = <1>;
	};

	dip_top_dip1_clk: syscon@15110000 {
		compatible = "mediatek,mt6879-dip_top_dip1", "syscon";
		reg = <0 0x15110000 0 0x1000>;
		#clock-cells = <1>;
	};

	dip_nr_dip1_clk: syscon@15130000 {
		compatible = "mediatek,mt6879-dip_nr_dip1", "syscon";
		reg = <0 0x15130000 0 0x1000>;
		#clock-cells = <1>;
	};

	wpe1_dip1_clk: syscon@15220000 {
		compatible = "mediatek,mt6879-wpe1_dip1", "syscon";
		reg = <0 0x15220000 0 0x1000>;
		#clock-cells = <1>;
	};

	ipesys_clk: syscon@15330000 {
		compatible = "mediatek,mt6879-ipesys", "syscon";
		reg = <0 0x15330000 0 0x1000>;
		#clock-cells = <1>;
	};

	wpe2_dip1_clk: syscon@15520000 {
		compatible = "mediatek,mt6879-wpe2_dip1", "syscon";
		reg = <0 0x15520000 0 0x1000>;
		#clock-cells = <1>;
	};

	wpe3_dip1_clk: syscon@15620000 {
		compatible = "mediatek,mt6879-wpe3_dip1", "syscon";
		reg = <0 0x15620000 0 0x1000>;
		#clock-cells = <1>;
	};

	vdec_gcon_base_clk: syscon@1602f000 {
		compatible = "mediatek,mt6879-vdec_gcon_base", "syscon";
		reg = <0 0x1602f000 0 0x1000>;
		#clock-cells = <1>;
	};

	venc_gcon_clk: syscon@17000000 {
		compatible = "mediatek,mt6879-vencsys", "syscon";
		reg = <0 0x17000000 0 0x1000>;
		#clock-cells = <1>;
	};

	apu_rcx_config_clk: syscon@19020000 {
		compatible = "mediatek,mt6879-apu_rcx_config", "syscon";
		reg = <0 0x19020000 0 0x1000>;
		#clock-cells = <1>;
	};

	apu_rcx_vcore_config_clk: syscon@190e0000 {
		compatible = "mediatek,mt6879-apu_rcx_vcore_config", "syscon";
		reg = <0 0x190e0000 0 0x1000>;
		#clock-cells = <1>;
	};

	apu_pll_ctrl_clk: syscon@190f3000 {
		compatible = "mediatek,mt6879-apu_pll_ctrl", "syscon";
		reg = <0 0x190f3000 0 0x1000>;
		#clock-cells = <1>;
	};

	mvpu0_top_config_clk: syscon@1912b000 {
		compatible = "mediatek,mt6879-mvpu0_top_config", "syscon";
		reg = <0 0x1912b000 0 0x1000>;
		#clock-cells = <1>;
	};

	apu_dla_0_config_clk: syscon@19130000 {
		compatible = "mediatek,mt6879-apu_dla_0_config", "syscon";
		reg = <0 0x19130000 0 0x1000>;
		#clock-cells = <1>;
	};

	apu_acx_config_clk: syscon@1913c000 {
		compatible = "mediatek,mt6879-apu_acx_config", "syscon";
		reg = <0 0x1913c000 0 0x1000>;
		#clock-cells = <1>;
	};

	scpsys: power-controller@1C001000 {
		compatible = "mediatek,mt6879-scpsys", "syscon";
		reg = <0 0x1C001000 0 0x1000>;
		#power-domain-cells = <1>;
		infracfg = <&infracfg_ao_clk>;
		vlpcfg = <&vlpcfg_bus_clk>;
	};

	vlpcfg_bus_clk: syscon@1C00C000 {
		compatible = "mediatek,mt6879-vlpcfg_bus", "syscon";
		reg = <0 0x1C00C000 0 0x1000>;
	};

	vlp_cksys_clk: syscon@1C013000 {
		compatible = "mediatek,mt6879-vlp_cksys", "syscon";
		reg = <0 0x1C013000 0 0x1000>;
		#clock-cells = <1>;
	};

	cam_main_r1a_clk: syscon@1a000000 {
		compatible = "mediatek,mt6879-cam_main_r1a", "syscon";
		reg = <0 0x1a000000 0 0x1000>;
		#clock-cells = <1>;
	};

	camsys_rawa_clk: syscon@1a04f000 {
		compatible = "mediatek,mt6879-camsys_rawa", "syscon";
		reg = <0 0x1a04f000 0 0x1000>;
		#clock-cells = <1>;
	};

	camsys_yuva_clk: syscon@1a06f000 {
		compatible = "mediatek,mt6879-camsys_yuva", "syscon";
		reg = <0 0x1a06f000 0 0x1000>;
		#clock-cells = <1>;
	};

	camsys_rawb_clk: syscon@1a08f000 {
		compatible = "mediatek,mt6879-camsys_rawb", "syscon";
		reg = <0 0x1a08f000 0 0x1000>;
		#clock-cells = <1>;
	};

	camsys_yuvb_clk: syscon@1a0af000 {
		compatible = "mediatek,mt6879-camsys_yuvb", "syscon";
		reg = <0 0x1a0af000 0 0x1000>;
		#clock-cells = <1>;
	};

	camsys_mraw_clk: syscon@1a170000 {
		compatible = "mediatek,mt6879-camsys_mraw", "syscon";
		reg = <0 0x1a170000 0 0x1000>;
		#clock-cells = <1>;
	};

	ccu_main_clk: syscon@1b200000 {
		compatible = "mediatek,mt6879-ccu", "syscon";
		reg = <0 0x1b200000 0 0x1000>;
		#clock-cells = <1>;
	};

	adsp_clk: syscon@1e000000 {
		compatible = "mediatek,mt6879-adsp", "syscon";
		reg = <0 0x1e000000 0 0x1000>;
		#clock-cells = <1>;
	};

	afe_clk: syscon@1e100000 {
		compatible = "mediatek,mt6879-afe", "syscon";
		reg = <0 0x1e100000 0 0x1000>;
		#clock-cells = <1>;
	};

	mminfra_config_clk: syscon@1e800000 {
		compatible = "mediatek,mt6879-mminfra_config", "syscon";
		reg = <0 0x1e800000 0 0x1000>;
		#clock-cells = <1>;
	};

	gce_d_clk: syscon@1e980000 {
		compatible = "mediatek,mt6879-gce_d", "syscon";
		reg = <0 0x1e980000 0 0x1000>;
		#clock-cells = <1>;
	};

	gce_m_clk: syscon@1e990000 {
		compatible = "mediatek,mt6879-gce_m", "syscon";
		reg = <0 0x1e990000 0 0x1000>;
		#clock-cells = <1>;
	};

	mdpsys_config_clk: syscon@1f000000 {
		compatible = "mediatek,mt6879-mdpsys", "syscon";
		reg = <0 0x1f000000 0 0x1000>;
		#clock-cells = <1>;
	};

	mtk_iommu_debug {
			compatible = "mediatek,mt6879-iommu-debug";
	};

	disp_iommu_bank1: iommu@1e803000 {
			compatible = "mediatek,common-disp-iommu-bank1";
		  mediatek,bank-id = <1>;
			reg = <0 0x1e803000 0 0x1000>;
			interrupts = <GIC_SPI 424 IRQ_TYPE_LEVEL_HIGH 0>;
	};

	disp_iommu_bank2: iommu@1e804000 {
			compatible = "mediatek,common-disp-iommu-bank2";
			mediatek,bank-id = <2>;
			reg = <0 0x1e804000 0 0x1000>;
			interrupts = <GIC_SPI 425 IRQ_TYPE_LEVEL_HIGH 0>;
	};

	disp_iommu_bank3: iommu@1e805000 {
			compatible = "mediatek,common-disp-iommu-bank3";
			mediatek,bank-id = <3>;
			reg = <0 0x1e805000 0 0x1000>;
			interrupts = <GIC_SPI 426 IRQ_TYPE_LEVEL_HIGH 0>;
	};

	disp_iommu_bank4: iommu@1e806000 {
			compatible = "mediatek,common-disp-iommu-bank4";
			mediatek,bank-id = <4>;
			reg = <0 0x1e806000 0 0x1000>;
			interrupts = <GIC_SPI 427 IRQ_TYPE_LEVEL_HIGH 0>;
	};

	disp_iommu: iommu@1e802000 {
			compatible = "mediatek,mt6879-disp-iommu";
			reg = <0 0x1e802000 0 0x1000>;
			mediatek,iommu_banks = <&disp_iommu_bank1 &disp_iommu_bank2
						&disp_iommu_bank3 &disp_iommu_bank4>;
			interrupts = <GIC_SPI 423 IRQ_TYPE_LEVEL_HIGH 0>;
			#iommu-cells = <1>;
	};

	peri_iommu_m4_bank1: iommu@10331000 {
			compatible = "mediatek,common-peri-iommu-m4-bank1";
			mediatek,bank-id = <1>;
			reg = <0 0x10331000 0 0x1000>;
	};

	peri_iommu_m4_bank2: iommu@10332000 {
			compatible = "mediatek,common-peri-iommu-m4-bank2";
			mediatek,bank-id = <2>;
			reg = <0 0x10332000 0 0x1000>;
	};

	peri_iommu_m4_bank3: iommu@10333000 {
			compatible = "mediatek,common-peri-iommu-m4-bank3";
			mediatek,bank-id = <3>;
			reg = <0 0x10333000 0 0x1000>;
	};

	peri_iommu_m4_bank4: iommu@10334000 {
			compatible = "mediatek,common-peri-iommu-m4-bank4";
			mediatek,bank-id = <4>;
			reg = <0 0x10334000 0 0x1000>;
	};

	peri_iommu_m4: iommu@10330000 {
			compatible = "mediatek,mt6879-peri-iommu-m4";
			reg = <0 0x10330000 0 0x1000>;
			mediatek,iommu_banks = <&peri_iommu_m4_bank1 &peri_iommu_m4_bank2
						&peri_iommu_m4_bank3 &peri_iommu_m4_bank4>;
			#iommu-cells = <1>;
	};

	peri_iommu_m6_bank1: iommu@10336000 {
			compatible = "mediatek,common-peri-iommu-m6-bank1";
			mediatek,bank-id = <1>;
			reg = <0 0x10336000 0 0x1000>;
	};

	peri_iommu_m6_bank2: iommu@10337000 {
			compatible = "mediatek,common-peri-iommu-m6-bank2";
			mediatek,bank-id = <2>;
			reg = <0 0x10337000 0 0x1000>;
	};

	peri_iommu_m6_bank3: iommu@10338000 {
			compatible = "mediatek,common-peri-iommu-m6-bank3";
			mediatek,bank-id = <3>;
			reg = <0 0x10338000 0 0x1000>;
	};

	peri_iommu_m6_bank4: iommu@10339000 {
			compatible = "mediatek,common-peri-iommu-m6-bank4";
			mediatek,bank-id = <4>;
			reg = <0 0x10339000 0 0x1000>;
	};

	peri_iommu_m6: iommu@10335000 {
			compatible = "mediatek,mt6879-peri-iommu-m6";
			reg = <0 0x10335000 0 0x1000>;
			mediatek,iommu_banks = <&peri_iommu_m6_bank1 &peri_iommu_m6_bank2
						&peri_iommu_m6_bank3 &peri_iommu_m6_bank4>;
			#iommu-cells = <1>;
	};

	peri_iommu_m7_bank1: iommu@1033b000 {
			compatible = "mediatek,common-peri-iommu-m7-bank1";
			mediatek,bank-id = <1>;
			reg = <0 0x1033b000 0 0x1000>;
	};

	peri_iommu_m7_bank2: iommu@1033c000 {
			compatible = "mediatek,common-peri-iommu-m7-bank2";
			mediatek,bank-id = <2>;
			reg = <0 0x1033c000 0 0x1000>;
	};

	peri_iommu_m7_bank3: iommu@1033d000 {
			compatible = "mediatek,common-peri-iommu-m7-bank3";
			mediatek,bank-id = <3>;
			reg = <0 0x1033d000 0 0x1000>;
	};

	peri_iommu_m7_bank4: iommu@1033e000 {
			compatible = "mediatek,common-peri-iommu-m7-bank4";
			mediatek,bank-id = <4>;
			reg = <0 0x1033e000 0 0x1000>;
	};

	peri_iommu_m7: iommu@1033a000 {
			compatible = "mediatek,mt6879-peri-iommu-m7";
			reg = <0 0x1033a000 0 0x1000>;
			mediatek,iommu_banks = <&peri_iommu_m7_bank1 &peri_iommu_m7_bank2
						&peri_iommu_m7_bank3 &peri_iommu_m7_bank4>;
			#iommu-cells = <1>;
	};

	apu_iommu0_bank1: iommu@19011000 {
			compatible = "mediatek,common-apu-iommu0-bank1";
			mediatek,bank-id = <1>;
			reg = <0 0x19011000 0 0x1000>;
			interrupts = <GIC_SPI 580 IRQ_TYPE_LEVEL_HIGH 0>;
	};

	apu_iommu0_bank2: iommu@19012000 {
			compatible = "mediatek,common-apu-iommu0-bank2";
			mediatek,bank-id = <2>;
			reg = <0 0x19012000 0 0x1000>;
			interrupts = <GIC_SPI 581 IRQ_TYPE_LEVEL_HIGH 0>;
	};

	apu_iommu0_bank3: iommu@19013000 {
			compatible = "mediatek,common-apu-iommu0-bank3";
			mediatek,bank-id = <3>;
			reg = <0 0x19013000 0 0x1000>;
			interrupts = <GIC_SPI 582 IRQ_TYPE_LEVEL_HIGH 0>;
	};

	apu_iommu0_bank4: iommu@19014000 {
			compatible = "mediatek,common-apu-iommu0-bank4";
			mediatek,bank-id = <4>;
			reg = <0 0x19014000 0 0x1000>;
			interrupts = <GIC_SPI 583 IRQ_TYPE_LEVEL_HIGH 0>;
	};

	apu_iommu0: iommu@19010000 {
			compatible = "mediatek,mt6879-apu-iommu0";
			reg = <0 0x19010000 0 0x1000>;
			mediatek,iommu_banks = <&apu_iommu0_bank1 &apu_iommu0_bank2
						&apu_iommu0_bank3 &apu_iommu0_bank4>;
			interrupts = <GIC_SPI 579 IRQ_TYPE_LEVEL_HIGH 0>;
			#iommu-cells = <1>;
	};
};

#include "mediatek/cust_mt6879_msdc.dtsi"
